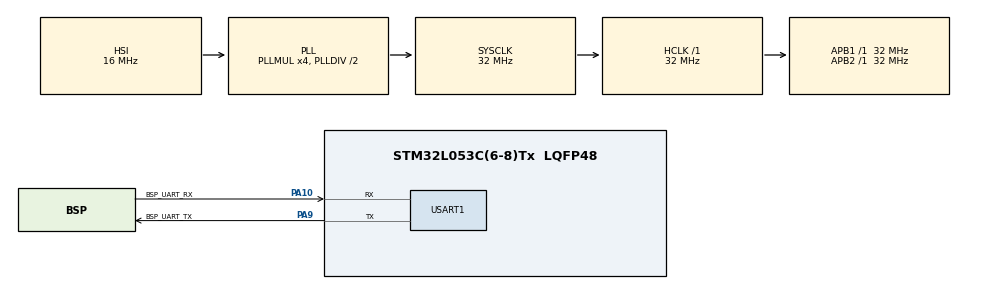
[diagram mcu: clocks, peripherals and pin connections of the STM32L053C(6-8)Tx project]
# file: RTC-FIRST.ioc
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Mcu.Family=STM32L0
Mcu.Name=STM32L053C(6-8)Tx
Mcu.Package=LQFP48
PA10.GPIO_Label=BSP_UART_RX
PA10.Mode=Asynchronous
PA10.Signal=USART1_RX
PA13.Mode=Serial_Wire
PA13.Signal=SYS_SWDIO
PA14.Mode=Serial_Wire
PA14.Signal=SYS_SWCLK
PA9.GPIO_Label=BSP_UART_TX
PA9.Mode=Asynchronous
PA9.Signal=USART1_TX
PC14-OSC32_IN.Mode=LSE-External-Oscillator
PC14-OSC32_IN.Signal=RCC_OSC32_IN
PC15-OSC32_OUT.Mode=LSE-External-Oscillator
PC15-OSC32_OUT.Signal=RCC_OSC32_OUT
PH0-OSC_IN.Mode=HSE-External-Oscillator
PH0-OSC_IN.Signal=RCC_OSC_IN
PH1-OSC_OUT.Mode=HSE-External-Oscillator
PH1-OSC_OUT.Signal=RCC_OSC_OUT
ProjectManager.HeapSize=0x200
ProjectManager.StackSize=0x400
ProjectManager.TargetToolchain=STM32CubeIDE
RCC.AHBFreq_Value=32000000
RCC.APB1Freq_Value=32000000
RCC.APB1TimFreq_Value=32000000
RCC.APB2Freq_Value=32000000
RCC.APB2TimFreq_Value=32000000
RCC.HCLKFreq_Value=32000000
RCC.HSE_VALUE=8000000
RCC.HSI16_VALUE=16000000
RCC.HSI48MClockSelection=RCC_USBCLKSOURCE_HSI48
RCC.HSI48_VALUE=48000000
RCC.HSI_VALUE=16000000
RCC.MSI_VALUE=2097000
RCC.PLLMUL=RCC_PLLMUL_4
RCC.RTCClockSelection=RCC_RTCCLKSOURCE_LSI
RCC.RTCClockSelectionVirtual=RCC_RTCCLKSOURCE_LSE
RCC.SYSCLKFreq_VALUE=32000000
RCC.SYSCLKSource=RCC_SYSCLKSOURCE_PLLCLK
RCC.VCOOutputFreq_Value=64000000
RTC.Date=2
RTC.Hours=5
RTC.Minutes=30
RTC.Month=RTC_MONTH_AUGUST
RTC.WeekDay=RTC_WEEKDAY_WEDNESDAY
RTC.Year=23
USART1.VirtualMode-Asynchronous=VM_ASYNC
VP_RTC_VS_RTC_Activate.Mode=RTC_Enabled
VP_RTC_VS_RTC_Calendar.Mode=RTC_Calendar
board=STM32L0538-DISCO

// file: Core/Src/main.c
/* USER CODE BEGIN Header */
/**
 ******************************************************************************
 * @file           : main.c
 * @brief          : Main program body
 ******************************************************************************
 * @attention
 *
 * Copyright (c) 2023 STMicroelectronics.
 * All rights reserved.
 *
 * This software is licensed under terms that can be found in the LICENSE file
 * in the root directory of this software component.
 * If no LICENSE file comes with this software, it is provided AS-IS.
 *
 ******************************************************************************
 */
/* USER CODE END Header */
#include "main.h"

/* USER CODE BEGIN Includes */
#include <stdio.h>
#include <string.h>
/* USER CODE END Includes */

/* USER CODE BEGIN PTD */
char date[30];
char time[30];
RTC_TimeTypeDef sTime;
RTC_DateTypeDef sDate;
/* USER CODE END PTD */

RTC_HandleTypeDef hrtc;

UART_HandleTypeDef huart1;

void SystemClock_Config(void);
static void MX_GPIO_Init(void);
static void MX_RTC_Init(void);
static void MX_USART1_UART_Init(void);

int main(void)
{

  /* MCU Configuration--------------------------------------------------------*/

  /* Reset of all peripherals, Initializes the Flash interface and the Systick. */
  HAL_Init();

  /* Configure the system clock */
  SystemClock_Config();

  /* Initialize all configured peripherals */
  MX_GPIO_Init();
  MX_RTC_Init();
  MX_USART1_UART_Init();
  /* USER CODE BEGIN 2 */
	HAL_RTC_GetTime(&hrtc, &sTime, RTC_FORMAT_BIN);
	HAL_RTC_GetDate(&hrtc, &sDate, RTC_FORMAT_BIN);
  /* USER CODE END 2 */

  /* Infinite loop */
	while (1) {

    /* USER CODE BEGIN 3 */
		HAL_RTC_GetTime(&hrtc, &sTime, RTC_FORMAT_BIN);
		HAL_RTC_GetDate(&hrtc, &sDate, RTC_FORMAT_BIN);
		sprintf(time, "Time: %02d.%02d.%02d\r\n", sTime.Hours, sTime.Minutes,
				sTime.Seconds);
		sprintf(date, "Date: %02d.%02d.%02d\t", sDate.Date, sDate.Month,
				sDate.Year);

		HAL_UART_Transmit(&huart1, (uint8_t*) date, sizeof(date), 200);

		HAL_UART_Transmit(&huart1, (uint8_t*) time, sizeof(time), 200);
		HAL_Delay(1000);
	}
  /* USER CODE END 3 */
}

void SystemClock_Config(void)
{
  RCC_OscInitTypeDef RCC_OscInitStruct = {0};
  RCC_ClkInitTypeDef RCC_ClkInitStruct = {0};
  RCC_PeriphCLKInitTypeDef PeriphClkInit = {0};

  /** Configure the main internal regulator output voltage
  */
  __HAL_PWR_VOLTAGESCALING_CONFIG(PWR_REGULATOR_VOLTAGE_SCALE1);

  /** Initializes the RCC Oscillators according to the specified parameters
  * in the RCC_OscInitTypeDef structure.
  */
  RCC_OscInitStruct.OscillatorType = RCC_OSCILLATORTYPE_HSI|RCC_OSCILLATORTYPE_LSI;
  RCC_OscInitStruct.HSIState = RCC_HSI_ON;
  RCC_OscInitStruct.HSICalibrationValue = RCC_HSICALIBRATION_DEFAULT;
  RCC_OscInitStruct.LSIState = RCC_LSI_ON;
  RCC_OscInitStruct.PLL.PLLState = RCC_PLL_ON;
  RCC_OscInitStruct.PLL.PLLSource = RCC_PLLSOURCE_HSI;
  RCC_OscInitStruct.PLL.PLLMUL = RCC_PLLMUL_4;
  RCC_OscInitStruct.PLL.PLLDIV = RCC_PLLDIV_2;
  if (HAL_RCC_OscConfig(&RCC_OscInitStruct) != HAL_OK)
  {
    Error_Handler();
  }

  /** Initializes the CPU, AHB and APB buses clocks
  */
  RCC_ClkInitStruct.ClockType = RCC_CLOCKTYPE_HCLK|RCC_CLOCKTYPE_SYSCLK
                              |RCC_CLOCKTYPE_PCLK1|RCC_CLOCKTYPE_PCLK2;
  RCC_ClkInitStruct.SYSCLKSource = RCC_SYSCLKSOURCE_PLLCLK;
  RCC_ClkInitStruct.AHBCLKDivider = RCC_SYSCLK_DIV1;
  RCC_ClkInitStruct.APB1CLKDivider = RCC_HCLK_DIV1;
  RCC_ClkInitStruct.APB2CLKDivider = RCC_HCLK_DIV1;

  if (HAL_RCC_ClockConfig(&RCC_ClkInitStruct, FLASH_LATENCY_1) != HAL_OK)
  {
    Error_Handler();
  }
  PeriphClkInit.PeriphClockSelection = RCC_PERIPHCLK_USART1|RCC_PERIPHCLK_RTC;
  PeriphClkInit.Usart1ClockSelection = RCC_USART1CLKSOURCE_PCLK2;
  PeriphClkInit.RTCClockSelection = RCC_RTCCLKSOURCE_LSI;
  if (HAL_RCCEx_PeriphCLKConfig(&PeriphClkInit) != HAL_OK)
  {
    Error_Handler();
  }
}

static void MX_RTC_Init(void)
{

  RTC_TimeTypeDef sTime = {0};
  RTC_DateTypeDef sDate = {0};

  /** Initialize RTC Only
  */
  hrtc.Instance = RTC;
  hrtc.Init.HourFormat = RTC_HOURFORMAT_24;
  hrtc.Init.AsynchPrediv = 127;
  hrtc.Init.SynchPrediv = 255;
  hrtc.Init.OutPut = RTC_OUTPUT_DISABLE;
  hrtc.Init.OutPutRemap = RTC_OUTPUT_REMAP_NONE;
  hrtc.Init.OutPutPolarity = RTC_OUTPUT_POLARITY_HIGH;
  hrtc.Init.OutPutType = RTC_OUTPUT_TYPE_OPENDRAIN;
  if (HAL_RTC_Init(&hrtc) != HAL_OK)
  {
    Error_Handler();
  }

  /** Initialize RTC and set the Time and Date
  */
  sTime.Hours = 0x5;
  sTime.Minutes = 0x30;
  sTime.Seconds = 0x0;
  sTime.DayLightSaving = RTC_DAYLIGHTSAVING_NONE;
  sTime.StoreOperation = RTC_STOREOPERATION_RESET;
  if (HAL_RTC_SetTime(&hrtc, &sTime, RTC_FORMAT_BCD) != HAL_OK)
  {
    Error_Handler();
  }
  sDate.WeekDay = RTC_WEEKDAY_WEDNESDAY;
  sDate.Month = RTC_MONTH_AUGUST;
  sDate.Date = 0x2;
  sDate.Year = 0x23;

  if (HAL_RTC_SetDate(&hrtc, &sDate, RTC_FORMAT_BCD) != HAL_OK)
  {
    Error_Handler();
  }

}

static void MX_USART1_UART_Init(void)
{

  huart1.Instance = USART1;
  huart1.Init.BaudRate = 115200;
  huart1.Init.WordLength = UART_WORDLENGTH_8B;
  huart1.Init.StopBits = UART_STOPBITS_1;
  huart1.Init.Parity = UART_PARITY_NONE;
  huart1.Init.Mode = UART_MODE_TX_RX;
  huart1.Init.HwFlowCtl = UART_HWCONTROL_NONE;
  huart1.Init.OverSampling = UART_OVERSAMPLING_16;
  huart1.Init.OneBitSampling = UART_ONE_BIT_SAMPLE_DISABLE;
  huart1.AdvancedInit.AdvFeatureInit = UART_ADVFEATURE_NO_INIT;
  if (HAL_UART_Init(&huart1) != HAL_OK)
  {
    Error_Handler();
  }

}

static void MX_GPIO_Init(void)
{

  /* GPIO Ports Clock Enable */
  __HAL_RCC_GPIOC_CLK_ENABLE();
  __HAL_RCC_GPIOH_CLK_ENABLE();
  __HAL_RCC_GPIOA_CLK_ENABLE();

}

void Error_Handler(void)
{
	__disable_irq();
	while (1) {
	}
}
